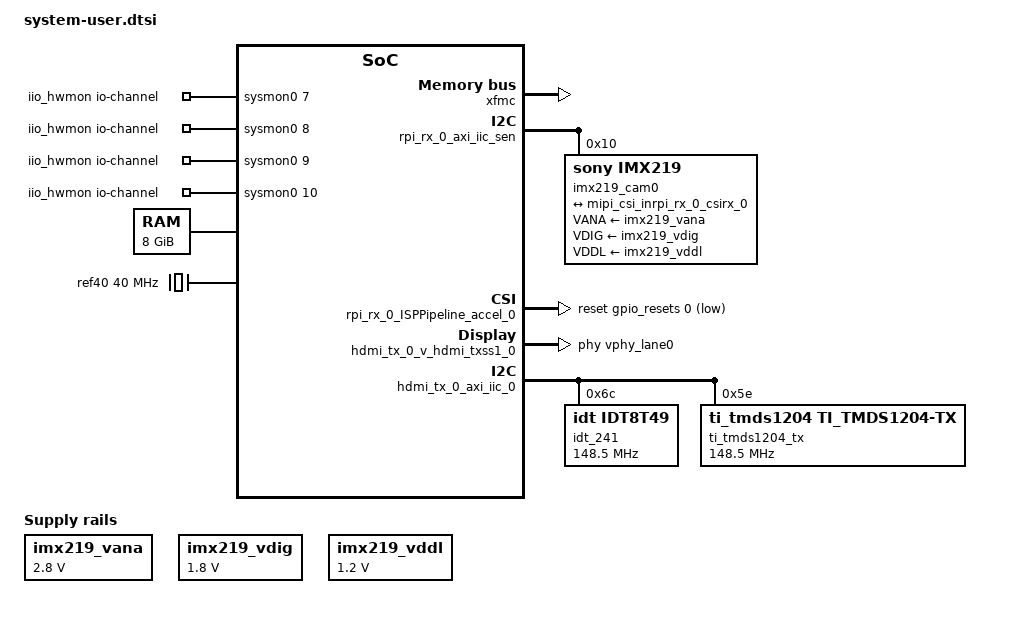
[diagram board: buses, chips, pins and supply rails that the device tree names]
/include/ "system-conf.dtsi"
/ {

	chosen {
		//bootargs = "console=ttyAMA0  earlycon=pl011,mmio32,0xFF000000,115200n8 clk_ignore_unused root=/dev/mmcblk0p2 rw rootwait cma=6G";
		bootargs = "console=ttyAMA0  earlycon=pl011,mmio32,0xFF000000,115200n8 clk_ignore_unused root=/dev/mmcblk0p2 rw rootwait";
		stdout-path = "serial0:115200n8";
	};

	iio_hwmon {
		compatible = "iio-hwmon";
		io-channels = <&sysmon0 7>, <&sysmon0 8>, <&sysmon0 9>, <&sysmon0 10>;
	};

	//memorynoc_ddr4: memory@0 {
	//	device_type = "memory";
	//	reg = <0x0 0x00000000 0x0 0x80000000>, <0x8 0x00000000 0x0 0x80000000>;
	//};

	memorynoc_lpddr4: memory@50000000000 {
		device_type = "memory";
		reg = <0x00000500 0x00000000 0x00000002 0x00000000>;
	};

	reserved-memory {
		#address-cells = <2>;
		#size-cells = <2>;
		ranges;

		video_reserved: cap_buf@0 {
			compatible = "shared-dma-pool";
			reg = <0x8 0x0 0x0 0x80000000>;
			reusable;
		};

		reserved: buffer@0 {
			compatible = "shared-dma-pool";
			reusable;
			reg = <0x500 0x0 0x2 0x0>;
			linux,cma-default;
		};
	};

};

&cpu_opp_table {
    // add cpu freq 1.35GHz
    opp04 {
       opp-hz = /bits/ 64 <1349986450>;
        opp-microvolt = <1000000>;
        clock-latency-ns = <500000>;
    };
};

&sysmon0 {
    #io-channel-cells = <1>;
};

#include "i2c0_mux_conf.dtsi"


//#include "mipi-2.dtsi"
//#include "display.dtsi"

&amba_pl {
	imx219_clk: imx219_clk {
		#clock-cells = <0x0>;
		clock-frequency = <24000000>;
		compatible = "fixed-clock";
	};


	imx219_vana: fixedregulator@3 {
		compatible = "regulator-fixed";
		regulator-name = "imx219_vana";
		regulator-min-microvolt = <2800000>;
		regulator-max-microvolt = <2800000>;
		enable-active-high;
	};

	imx219_vdig: fixedregulator@4 {
		compatible = "regulator-fixed";
		regulator-name = "imx219_vdig";
		regulator-min-microvolt = <1800000>;
		regulator-max-microvolt = <1800000>;
	};

	imx219_vddl: fixedregulator@5 {
		compatible = "regulator-fixed";
		regulator-name = "imx219_vddl";
		regulator-min-microvolt = <1200000>;
		regulator-max-microvolt = <1200000>;
	};
};

/* rpi_rx_0 - IIC */

&rpi_rx_0_axi_iic_sen {
	imx219_cam0: sensor@10 {
		compatible = "sony,imx219";
		reg = <0x10>;
		clocks = <&imx219_clk>;
		VANA-supply = <&imx219_vana>;   /* 2.8v */
		VDIG-supply = <&imx219_vdig>;   /* 1.8v */
		VDDL-supply = <&imx219_vddl>;   /* 1.2v */

		port {
		     imx219_cam0_0: endpoint {
			remote-endpoint = <&mipi_csi_inrpi_rx_0_csirx_0>;
			data-lanes = <1 2>;
			link-frequencies = /bits/ 64 <456000000>;
			};
		};
	};
};

/* rpi_rx_0 - csirx_0 */

&rpi_rx_0_csirx_0 {
	//compatible = "xlnx,mipi-csi2-rx-subsystem-5.3", "xlnx,mipi-csi2-rx-subsystem-5.0";
	compatible = "xlnx,mipi-csi2-rx-subsystem-5.2", "xlnx,mipi-csi2-rx-subsystem-5.0";
	xlnx,en-active-lanes;
};

&mipi_csi_inrpi_rx_0_csirx_0 {
	remote-endpoint = <&imx219_cam0_0>;
};

/* rpi_rx_0 - ISPPipeline_accel_0 */

&rpi_rx_0_ISPPipeline_accel_0 {
	//xlnx,max-height = /bits/ 16 <2160>;
	//xlnx,max-width = /bits/ 16 <3840>;
	//xlnx,pawb = /bits/ 16 <350>;
	//xlnx,rgain = /bits/ 16 <128>;
	
	//xlnx,max-height = <1232>;
	// Causes following error:
	//    [] xilinx-isppipeline a4020000.ISPPipeline_accel: Invalid height in dt
	//    [] xilinx-isppipeline: probe of a4020000.ISPPipeline_accel failed with error -22
	// Driver is failing following check:
	//    #define XISP_MAX_HEIGHT			(4320)
	//    #define XISP_MAX_WIDTH			(8192)
	//    #define XISP_MIN_HEIGHT			(64)
	//    #define XISP_MIN_WIDTH			(64)
	//    ...
	//    if (xisp->max_height > XISP_MAX_HEIGHT ||
	//    	xisp->max_height < XISP_MIN_HEIGHT) {
	//    	dev_err(dev, "Invalid height in dt");
	//    	return -EINVAL;
	//    };
	//    ...
	//xlnx,max-width = <1920>;
	xlnx,max-height = /bits/ 16 <1232>;
	xlnx,max-width = /bits/ 16 <1920>;	
	xlnx,rgain = /bits/ 16 <128>;
	xlnx,bgain = /bits/ 16 <210>;
	xlnx,pawb = /bits/ 16 <350>;
	
	//reset-gpios = <&gpio_resets 0 0 1>;
	// As defined in auto-generated pl.dtsi, causes boot to hang ...
	// Probably since CPU is trying to access core while it is in reset
	reset-gpios = <&gpio_resets 0 1>;
};

&rpi_rx_0_ISPPipeline_accel_0rpi_rx_0_csirx_0 {
	//remote-endpoint = <&isppipeline_inrpi_rx_0_ISPPipeline_accel_0>;
	remote-endpoint = <&mipi_csirx_outrpi_rx_0_csirx_0>;
	xlnx,video-width = <10>;
};
&rpi_rx_0_ISPPipeline_accel_0rpi_rx_0_v_proc_csc_0  {
	//remote-endpoint = <&v_proc_ssrpi_rx_0_ISPPipeline_accel_0>;
	remote-endpoint = <&sca_inrpi_rx_0_v_proc_csc_0>;
	xlnx,video-width = <8>;
};

/* rpi_rx_0 - v_proc_csc_0 */

&rpi_rx_0_v_proc_csc_0 {
	//compatible = "xlnx,v-proc-ss-2.3", "xlnx,vpss-scaler-2.2", "xlnx,v-vpss-scaler-2.2", "xlnx,vpss-scaler";
	compatible = "xlnx,v-vpss-scaler-2.2";
};

&scaler_port0rpi_rx_0_v_proc_csc_0 {
	sca_inrpi_rx_0_v_proc_csc_0: endpoint {
		remote-endpoint = <&rpi_rx_0_ISPPipeline_accel_0rpi_rx_0_v_proc_csc_0>;
	};
};

/* hdmi_tx_0 - v_mix_0 */

&xx_mix_masterhdmi_tx_0_v_mix_0 {
	xlnx,vformat = "RG24";
};
			
/* hdmi_tx_0 - hdmiphy_ss - hdmi_gt_controller_0 */

&amba_pl {
	xfmc:xv_fmc {
		compatible = "vfmc";
	};
};
	
&hdmi_tx_0_hdmiphy_ss_hdmi_gt_controller_0 {
	//compatible = "xlnx,hdmi-gt-controller-1.0";
	compatible = "xlnx,v-hdmi-gt-controller-1.0";
	
	//clock-names = "gt_refclk1_odiv2", "gt_refclk2_odiv2", "sb_aclk", "axi4lite_aclk", "apb_clk";
	//clocks = <&misc_clk_1>, <&misc_clk_2>, <&misc_clk_0>, <&misc_clk_0>, <&misc_clk_0>;
	clock-names = "gt_refclk1_odiv2", "gt_refclk2_odiv2", "sb_aclk", "axi4lite_aclk", "apb_clk", "vid_phy_axi4lite_aclk", "drpclk", "tmds_clock", "link_clk";
	clocks = <&misc_clk_1>, <&misc_clk_2>, <&misc_clk_0>, <&misc_clk_0>, <&misc_clk_0>, <&versal_clk 65>, <&versal_clk 65>, <&idt_241 1>, <&idt_241 1>;

	xlnx,gt-direction = <0x1>;	

	xlnx,hdmi-connector = <&xfmc>;
			
	xlnx,rx-max-gt-line-rate = <0xc>;
	xlnx,tx-max-gt-line-rate = <0xc>;
	xlnx,transceiver-type = <8>;	
};

/* hdmi_tx_0 - hdmi_txss1_0 */

&hdmi_tx_0_v_hdmi_txss1_0 {
	//compatible = "xlnx,v-hdmi-txss1-1.2", "xlnx,v-hdmi-tx-ss-3.1";
	compatible = "xlnx,v-hdmi-txss1-1.2";

	//clock-names = "s_axi_cpu_aclk", "s_axis_audio_aclk", "video_clk", "frl_clk", "s_axis_video_aclk";
	//clocks = <&misc_clk_0>, <&misc_clk_0>, <&misc_clk_3>, <&misc_clk_4>, <&misc_clk_5>;
	clock-names = "s_axi_cpu_aclk", "link_clk", "video_clk", "frl_clk", "s_axis_video_aclk";
	clocks = <&misc_clk_0>, <&misc_clk_3>, <&misc_clk_3>, <&misc_clk_4>, <&misc_clk_3>;
	// misc_clk_3 == 300MHz
	// misc_clk_4 == 325MHz
	
	//phy-names = "hdmi-phy0", "hdmi-phy1", "hdmi-phy2";
	//phys = <&vphy_lane0 0 1 1 1>, <&vphy_lane1 0 1 1 1>, <&vphy_lane2 0 1 1 1>;
	phy-names = "hdmi-phy0", "hdmi-phy1", "hdmi-phy2", "hdmi-phy3";
	phys = <&vphy_lane0 0 1 1 1>, <&vphy_lane1 0 1 1 1>, <&vphy_lane2 0 1 1 1>, <&vphy_lane3 0 1 1 1>;
	
	xlnx,add-core-dbg = <0x0>;
	xlnx,add-mark-dbg = "false";
	xlnx,addr-width = <0xa>;
	xlnx,dsc-en = <0x0>;
	xlnx,dynamic-hdr = <0x0>;
	xlnx,exdes-axilite-freq = <0x64>;
	xlnx,exdes-nidru = "true";
	xlnx,exdes-rx-pll-selection = <0x0>;
	xlnx,exdes-topology = <0x0>;
	xlnx,exdes-tx-pll-selection = <0x1>;
	xlnx,frl-clk-freq-khz = <0x4f588>;
	xlnx,frl-sm-vcke = <0x0>;
	xlnx,hdmi-fb-enable = "false";
	xlnx,hdmi-version = <0x4>;
	xlnx,hpd-invert = "true";
	xlnx,hysteresis-level = <0x1ff>;
	xlnx,include-hdcp = "false";
	xlnx,include-hdcp-1-4 = "false";
	xlnx,include-hdcp-2-2 = "false";
	xlnx,include-low-reso-vid = "true";
	xlnx,include-yuv420-sup = "true";
	xlnx,input-pixels-per-clock = <0x4>;
	xlnx,max-bits-per-component = <0x8>;
	xlnx,max-frl-rate = <0x4>;
	xlnx,native-exdes-en = <0x0>;
	xlnx,num-of-gt-lane = <0x4>;
	xlnx,smartconnect-enable = "false";
	xlnx,validation-enable = "false";
	xlnx,vid-clk-freq-khz = <0x493e0>;
	xlnx,vid-interface = <0x0>;
	xlnx,video-mask-enable = <0x1>;
	xlnx,vrr-support = <0x1>;
	
	i2c-bus {
	};
};

/* hdmi_tx_0 - hdmi_ctrl_iic */

&amba_pl {
	ref40: ref40m {
		compatible = "fixed-clock";
		#clock-cells = <0>;
		clock-frequency = <40000000>;
	};
};

&hdmi_tx_0_axi_iic_0 {

	idt_241: clock-generator@6c {
		compatible = "idt,idt8t49";
		#clock-cells = <1>;
		reg = <0x6c>;
		clocks = <&ref40>;
		clock-frequency = <148500000>;
		clock-names = "input-xtal";
	};
	
	ti_tmds1204_tx: ti_tmds1204-tx@5e {
		compatible = "ti_tmds1204,ti_tmds1204-tx";
		#clock-cells = <1>;
		reg = <0x5e>;
		clocks = <&ref40>;
		clock-frequency = <148500000>;
		clock-names = "input-xtal";
	};

};
